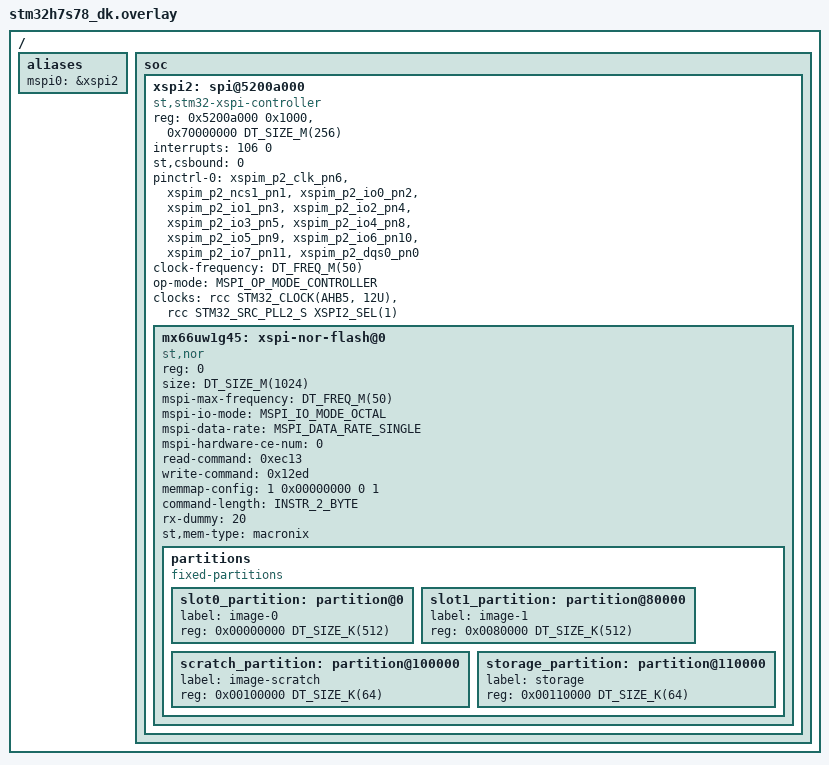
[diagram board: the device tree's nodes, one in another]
/*
 * Copyright (c) 2026 EXALT Technologies
 *
 * SPDX-License-Identifier: Apache-2.0
 */

/delete-node/ &xspi2;

/ {
	aliases {
		/* The sample gets the DT_ALIAS(flash0) as the mspi device */
		mspi0 = &xspi2;
	};

	soc {
		xspi2: spi@5200a000 {
			compatible = "st,stm32-xspi-controller";
			reg = <0x5200a000 0x1000>, <0x70000000 DT_SIZE_M(256)>;
			interrupts = <106 0>;
			st,csbound = <0>;
			pinctrl-0 = <&xspim_p2_clk_pn6 &xspim_p2_ncs1_pn1
				     &xspim_p2_io0_pn2 &xspim_p2_io1_pn3
				     &xspim_p2_io2_pn4 &xspim_p2_io3_pn5
				     &xspim_p2_io4_pn8 &xspim_p2_io5_pn9
				     &xspim_p2_io6_pn10 &xspim_p2_io7_pn11
				     &xspim_p2_dqs0_pn0>;
			clock-frequency = <DT_FREQ_M(50)>;
			pinctrl-names = "default";
			#address-cells = <1>;
			#size-cells = <0>;
			op-mode = "MSPI_OP_MODE_CONTROLLER";
			clock-names = "xspix", "xspi-ker";
			clocks = <&rcc STM32_CLOCK(AHB5, 12U)>,
				 <&rcc STM32_SRC_PLL2_S XSPI2_SEL(1)>;
			status = "okay";

			mx66uw1g45: xspi-nor-flash@0 {
				compatible = "st,nor", "mxicy,mx25u", "jedec,nor";
				reg = <0>;
				size = <DT_SIZE_M(1024)>;
				mspi-max-frequency = <DT_FREQ_M(50)>;
				mspi-io-mode = "MSPI_IO_MODE_OCTAL";
				mspi-data-rate = "MSPI_DATA_RATE_SINGLE";
				mspi-hardware-ce-num = <0>;
				read-command = <0xec13>;
				write-command = <0x12ed>;
				memmap-config = <1 0x00000000 0 1>;
				command-length = "INSTR_2_BYTE";
				rx-dummy = <20>;
				st,mem-type = "macronix";
				status = "okay";

				partitions {
					compatible = "fixed-partitions";
					#address-cells = <1>;
					#size-cells = <1>;

					slot0_partition: partition@0 {
						label = "image-0";
						reg = <0x00000000 DT_SIZE_K(512)>;
					};

					slot1_partition: partition@80000 {
						label = "image-1";
						reg = <0x0080000 DT_SIZE_K(512)>;
					};

					scratch_partition: partition@100000 {
						label = "image-scratch";
						reg = <0x00100000 DT_SIZE_K(64)>;
					};

					storage_partition: partition@110000 {
						label = "storage";
						reg = <0x00110000 DT_SIZE_K(64)>;
					};
				};
			};
		};
	};
};
